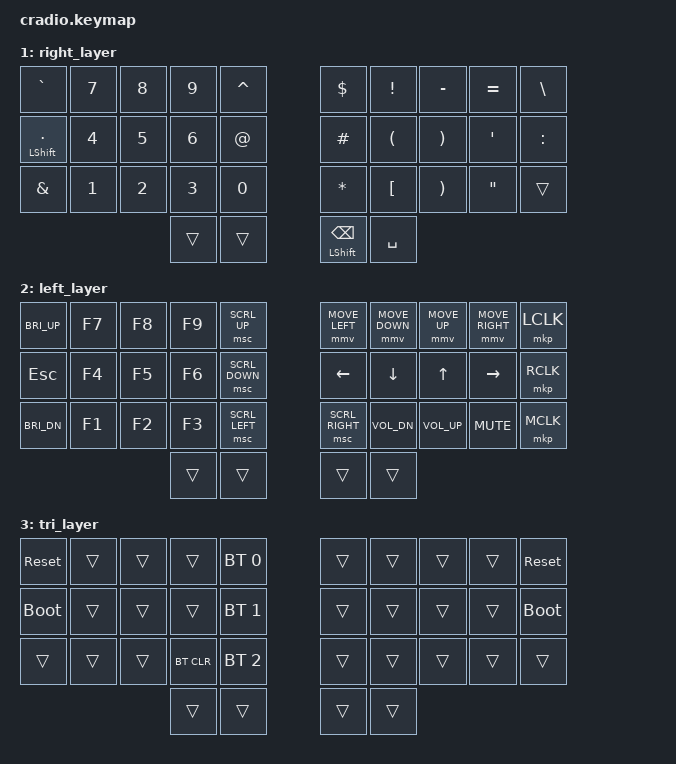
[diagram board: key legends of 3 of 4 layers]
// Copyright (c) 2022 The ZMK Contributors
// SPDX-License-Identifier: MIT

#include <behaviors.dtsi>
#include <dt-bindings/zmk/keys.h>
#include <dt-bindings/zmk/bt.h>

#define ZMK_POINTING_DEFAULT_MOVE_VAL 600
#define ZMK_POINTING_DEFUALT_SCRL_VAL 10
#include <dt-bindings/zmk/pointing.h>

/ {
    combos {
        compatible = "zmk,combos";
        combo_LESC {
            timeout-ms = <50>;
            key-positions = <16 17>;
            bindings = <&kp CAPS>;
        };
        combo_RESC {
            timeout-ms = <50>;
            key-positions = <12 13>;
            bindings = <&kp CAPS>;
        };
    };
};

// Home row mods macro
#define HRML(k1,k2,k3,k4) &ht LSHFT k1  &ht LALT k2  &ht LCTRL k3  &ht LGUI k4
#define HRMR(k1,k2,k3,k4) &ht RGUI k1  &ht RCTRL k2  &ht RALT k3  &ht RSHFT k4

/ {
    behaviors {
        ht: hold_tap {
            compatible = "zmk,behavior-hold-tap";
            #binding-cells = <2>;
            flavor = "balanced";
            tapping-term-ms = <220>;
            quick-tap-ms = <150>;
            require-prior-idle-ms = <100>;
            bindings = <&kp>, <&kp>;
        };
    };

    conditional_layers {
        compatible = "zmk,conditional-layers";
        tri_layer {
            if-layers = <1 2>;
            then-layer = <3>;
        };
    };

    keymap {
        compatible = "zmk,keymap";
        default_layer {
            bindings = <
        //╭──────────┬──────────┬──────────┬──────────┬──────────╮   ╭──────────┬──────────┬──────────┬──────────┬──────────╮
        //│  Q       │  W       │  E       │  R       │  T       │   │  Y       │  U       │  I       │  O       │  P       │
            &kp Q      &kp W      &kp E      &kp R      &kp T          &kp Y      &kp U      &kp I      &kp O      &kp P
        //├──────────┼──────────┼──────────┼──────────┼──────────┤   ├──────────┼──────────┼──────────┼──────────┼──────────┤
        //│  A       │  S       │  D       │  F       │  G       │   │  H       │  J       │  K       │  L       │ ; :      │
            HRML(A,        S,         D,         F)     &kp G          &kp H      HRMR(J,        K,         L,        SEMI)
        //├──────────┼──────────┼──────────┼──────────┼──────────┤   ├──────────┼──────────┼──────────┼──────────┼──────────┤
        //│  Z       │  X       │  C       │  V       │  B       │   │  N       │  M       │ , <      │ . >      │ / ?      │
            &kp Z      &kp X      &kp C      &kp V      &kp B          &kp N      &kp M      &kp COMMA  &kp DOT    &kp FSLH
        //╰──────────┴──────────┴──────────┼──────────┼──────────┤   ├──────────┼──────────┼──────────┴──────────┴──────────╯
                                            &kp ENTER   &lt 1 TAB     &kp BSPC    &lt 2 SPACE
        //                                 ╰──────────┴──────────╯   ╰──────────┴──────────╯
            >;
        };

        right_layer {
            bindings = <
        //╭─────────────      ┬──────────┬──────────┬──────────┬──────────╮   ╭──────────┬──────────┬──────────┬──────────┬──────────╮
        //│ ` ~               │ 7 &      │ 8 *      │ 9 (      │ ^        │   │ $        │ !        │ - _      │ = +      │ \ |       │
            &kp GRAVE           &kp N7     &kp N8     &kp N9     &kp CARET      &kp DLLR   &kp EXCL   &kp MINUS  &kp EQUAL  &kp BSLH 
        //├─────────────      ┼──────────┼──────────┼──────────┼──────────┤   ├──────────┼──────────┼──────────┼──────────┼──────────┤
        //│ .                 │ 4 $      │ 5 %      │ 6 ^      │ @        │   │ #        │ (        │ )        │ ' "      │ :        │
            &mt LSHIFT DOT      &kp N4     &kp N5     &kp N6     &kp AT         &kp HASH   &kp LPAR   &kp RPAR   &kp APOS    &kp COLON
        //├─────────────      ┼──────────┼──────────┼──────────┼──────────┤   ├──────────┼──────────┼──────────┼──────────┼──────────┤
        //│ &                 │ 1 !      │ 2 @      │ 3 #      │  0       │   │ *        │ [ {      │ ] }      │ "        │          │
           &kp AMPS             &kp N1     &kp N2     &kp N3     &kp N0         &kp STAR   &kp LBKT   &kp RPAR   &kp DQT    &trans
        //╰─────────────      ┴──────────┴──────────┼──────────┼──────────┤   ├──────────┼──────────┼──────────┴──────────┴──────────╯
                                             &trans     &trans         &mt LSHIFT BSPC &kp SPACE 
        //                                 ╰──────────┴──────────╯   ╰──────────┴──────────╯
            >;
        };

        left_layer {
            bindings = <
        //╭──────────────┬──────────┬──────────┬──────────┬──────────╮   ╭─────────────     ┬─────────────      ┬─────────────      ┬────────────  ─    ┬──────────╮
        //│ BRIGHT UP    │ F7       │ F8       │ F9       │ SCROLL UP│   │ M LEFT           │ M DOWN            │ M UP              │ M RIGHT           │ M CLICK  │
            &kp C_BRI_UP   &kp F7     &kp F8     &kp F9     &msc SCRL_UP   &mmv MOVE_LEFT     &mmv MOVE_DOWN      &mmv MOVE_UP        &mmv MOVE_RIGHT     &mkp LCLK
        //├──────────────┼──────────┼──────────┼──────────┼──────────┤   ├─────────────     ┼─────────────      ┼─────────────      ┼────────────  ─    ┼──────────┤
        //│ ESC          │ F4       │ F5       │ F6       │ SCROLL D │   │ LEFT             │ DOWN              │ UP                │ RIGHT             │ M RCLICK │
            &kp ESC        &kp F4     &kp F5     &kp F6     &msc SCRL_DOWN &kp LEFT           &kp DOWN            &kp UP              &kp RIGHT           &mkp RCLK
        //├──────────────┼──────────┼──────────┼──────────┼──────────┤   ├─────────────     ┼─────────────      ┼─────────────      ┼────────────  ─    ┼──────────┤
        //│ BRIGHT DOWN  │ F1       │ F2       │ F3       │ SCROLL L │   │ SCROLL R         │ VOL DOWN          │ VOL UP            │ MUTE              │ M MCLICK │
            &kp C_BRI_DN   &kp F1     &kp F2     &kp F3     &msc SCRL_LEFT &msc SCRL_RIGHT    &kp K_VOL_DN        &kp K_VOL_UP        &kp K_MUTE          &mkp MCLK
        //╰──────────────┴──────────┴──────────┼──────────┼──────────┤   ├─────────────     ┼─────────────      ┼─────────────      ┴────────────  ─    ┴──────────╯
                                             &trans     &trans         &trans             &trans
        //                                 ╰──────────┴──────────╯   ╰─────────────     ┴──────────╯
            >;
        };

        tri_layer {
            bindings = <
        //╭──────────┬──────────┬──────────┬──────────┬──────────╮   ╭──────────┬──────────┬──────────┬──────────┬──────────╮
        //│ RESET    │          │          │          │PROFILE 0 │   │          │          │          │          │  RESET   │
           &sys_reset  &trans     &trans     &trans    &bt BT_SEL 0    &trans     &trans     &trans     &trans    &sys_reset
        //├──────────┼──────────┼──────────┼──────────┼──────────┤   ├──────────┼──────────┼──────────┼──────────┼──────────┤
        //│BOOTLOADER│          │          │          │PROFILE 1 │   │          │          │          │          │BOOTLOADER│
          &bootloader  &trans     &trans     &trans    &bt BT_SEL 1    &trans     &trans     &trans     &trans    &bootloader
        //├──────────┼──────────┼──────────┼──────────┼──────────┤   ├──────────┼──────────┼──────────┼──────────┼──────────┤
        //│          │          │          │ CLEAR BT │PROFILE 2 │   │          │          │          │          │          │
            &trans     &trans     &trans    &bt BT_CLR &bt BT_SEL 2    &trans     &trans     &trans     &trans     &trans
        //╰──────────┴──────────┴──────────┼──────────┼──────────┤   ├──────────┼──────────┼──────────┴──────────┴──────────╯
                                             &trans     &trans         &trans     &trans
        //                                 ╰──────────┴──────────╯   ╰──────────┴──────────╯
            >;
        };
    };
};
